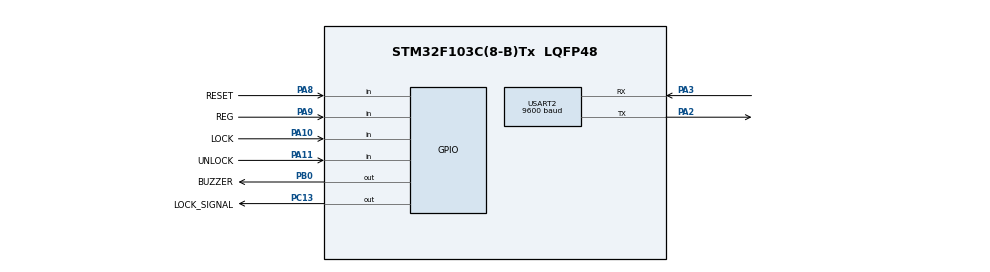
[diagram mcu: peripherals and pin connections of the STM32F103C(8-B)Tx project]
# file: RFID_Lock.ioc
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Mcu.Family=STM32F1
Mcu.Name=STM32F103C(8-B)Tx
Mcu.Package=LQFP48
NVIC.PriorityGroup=NVIC_PRIORITYGROUP_4
PA10.GPIO_Label=LOCK
PA10.GPIO_PuPd=GPIO_PULLUP
PA10.Signal=GPIO_Input
PA11.GPIO_Label=UNLOCK
PA11.GPIO_PuPd=GPIO_PULLUP
PA11.Signal=GPIO_Input
PA13.Mode=Serial_Wire
PA13.Signal=SYS_JTMS-SWDIO
PA14.Mode=Serial_Wire
PA14.Signal=SYS_JTCK-SWCLK
PA2.Mode=Asynchronous
PA2.Signal=USART2_TX
PA3.Mode=Asynchronous
PA3.Signal=USART2_RX
PA8.GPIO_Label=RESET
PA8.GPIO_PuPd=GPIO_PULLUP
PA8.Signal=GPIO_Input
PA9.GPIO_Label=REG
PA9.GPIO_PuPd=GPIO_PULLUP
PA9.Signal=GPIO_Input
PB0.GPIO_Label=BUZZER
PB0.GPIO_PuPd=GPIO_PULLUP
PB0.Signal=GPIO_Output
PC13-TAMPER-RTC.GPIO_Label=LOCK_SIGNAL
PC13-TAMPER-RTC.Signal=GPIO_Output
PD0-OSC_IN.Mode=HSE-External-Oscillator
PD0-OSC_IN.Signal=RCC_OSC_IN
PD1-OSC_OUT.Mode=HSE-External-Oscillator
PD1-OSC_OUT.Signal=RCC_OSC_OUT
ProjectManager.HeapSize=0x200
ProjectManager.StackSize=0x400
ProjectManager.TargetToolchain=STM32CubeIDE
RCC.APB1Freq_Value=8000000
RCC.APB2Freq_Value=8000000
USART2.BaudRate=9600
USART2.VirtualMode=VM_ASYNC
board=custom

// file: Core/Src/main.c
/* USER CODE BEGIN Header */
/**
  ******************************************************************************
  * @file           : main.c
  * @brief          : Main program body
  ******************************************************************************
  * @attention
  *
  * <h2><center>&copy; Copyright (c) 2022 STMicroelectronics.
  * All rights reserved.</center></h2>
  *
  * This software component is licensed by ST under BSD 3-Clause license,
  * the "License"; You may not use this file except in compliance with the
  * License. You may obtain a copy of the License at:
  *                        opensource.org/licenses/BSD-3-Clause
  *
  ******************************************************************************
  */
/* USER CODE END Header */
#include "main.h"

/* USER CODE BEGIN Includes */
#include "button.h"
#include "rc522.h"
#include "software_timer.h"
/* USER CODE END Includes */

UART_HandleTypeDef huart2;

/* USER CODE BEGIN PV */
MFRC522_Name RFID;
/* USER CODE END PV */

void SystemClock_Config(void);
static void MX_GPIO_Init(void);
static void MX_USART2_UART_Init(void);

int main(void)
{
	HAL_GPIO_WritePin(BUZZER_GPIO_Port, BUZZER_Pin, 1);

  /* MCU Configuration--------------------------------------------------------*/

  /* Reset of all peripherals, Initializes the Flash interface and the Systick. */
  HAL_Init();

  /* Configure the system clock */
  SystemClock_Config();

  /* Initialize all configured peripherals */
  MX_GPIO_Init();
  MX_USART2_UART_Init();
  /* USER CODE BEGIN 2 */
  MFRC522_Init(&RFID, &huart2);
  /* USER CODE END 2 */

  /* Infinite loop */
  while (1)
  {

  }
}

void SystemClock_Config(void)
{
  RCC_OscInitTypeDef RCC_OscInitStruct = {0};
  RCC_ClkInitTypeDef RCC_ClkInitStruct = {0};

  /** Initializes the RCC Oscillators according to the specified parameters
  * in the RCC_OscInitTypeDef structure.
  */
  RCC_OscInitStruct.OscillatorType = RCC_OSCILLATORTYPE_HSI;
  RCC_OscInitStruct.HSIState = RCC_HSI_ON;
  RCC_OscInitStruct.HSICalibrationValue = RCC_HSICALIBRATION_DEFAULT;
  RCC_OscInitStruct.PLL.PLLState = RCC_PLL_NONE;
  if (HAL_RCC_OscConfig(&RCC_OscInitStruct) != HAL_OK)
  {
    Error_Handler();
  }
  /** Initializes the CPU, AHB and APB buses clocks
  */
  RCC_ClkInitStruct.ClockType = RCC_CLOCKTYPE_HCLK|RCC_CLOCKTYPE_SYSCLK
                              |RCC_CLOCKTYPE_PCLK1|RCC_CLOCKTYPE_PCLK2;
  RCC_ClkInitStruct.SYSCLKSource = RCC_SYSCLKSOURCE_HSI;
  RCC_ClkInitStruct.AHBCLKDivider = RCC_SYSCLK_DIV1;
  RCC_ClkInitStruct.APB1CLKDivider = RCC_HCLK_DIV1;
  RCC_ClkInitStruct.APB2CLKDivider = RCC_HCLK_DIV1;

  if (HAL_RCC_ClockConfig(&RCC_ClkInitStruct, FLASH_LATENCY_0) != HAL_OK)
  {
    Error_Handler();
  }
}

static void MX_USART2_UART_Init(void)
{

  huart2.Instance = USART2;
  huart2.Init.BaudRate = 9600;
  huart2.Init.WordLength = UART_WORDLENGTH_8B;
  huart2.Init.StopBits = UART_STOPBITS_1;
  huart2.Init.Parity = UART_PARITY_NONE;
  huart2.Init.Mode = UART_MODE_TX_RX;
  huart2.Init.HwFlowCtl = UART_HWCONTROL_NONE;
  huart2.Init.OverSampling = UART_OVERSAMPLING_16;
  if (HAL_UART_Init(&huart2) != HAL_OK)
  {
    Error_Handler();
  }

}

static void MX_GPIO_Init(void)
{
  GPIO_InitTypeDef GPIO_InitStruct = {0};

  /* GPIO Ports Clock Enable */
  __HAL_RCC_GPIOC_CLK_ENABLE();
  __HAL_RCC_GPIOD_CLK_ENABLE();
  __HAL_RCC_GPIOA_CLK_ENABLE();
  __HAL_RCC_GPIOB_CLK_ENABLE();

  /*Configure GPIO pin Output Level */
  HAL_GPIO_WritePin(LOCK_SIGNAL_GPIO_Port, LOCK_SIGNAL_Pin, GPIO_PIN_RESET);

  /*Configure GPIO pin Output Level */
  HAL_GPIO_WritePin(BUZZER_GPIO_Port, BUZZER_Pin, GPIO_PIN_SET);

  /*Configure GPIO pin : LOCK_SIGNAL_Pin */
  GPIO_InitStruct.Pin = LOCK_SIGNAL_Pin;
  GPIO_InitStruct.Mode = GPIO_MODE_OUTPUT_PP;
  GPIO_InitStruct.Pull = GPIO_NOPULL;
  GPIO_InitStruct.Speed = GPIO_SPEED_FREQ_LOW;
  HAL_GPIO_Init(LOCK_SIGNAL_GPIO_Port, &GPIO_InitStruct);

  /*Configure GPIO pin : BUZZER_Pin */
  GPIO_InitStruct.Pin = BUZZER_Pin;
  GPIO_InitStruct.Mode = GPIO_MODE_OUTPUT_PP;
  GPIO_InitStruct.Pull = GPIO_PULLUP;
  GPIO_InitStruct.Speed = GPIO_SPEED_FREQ_LOW;
  HAL_GPIO_Init(BUZZER_GPIO_Port, &GPIO_InitStruct);

  /*Configure GPIO pins : RESET_Pin REG_Pin LOCK_Pin UNLOCK_Pin */
  GPIO_InitStruct.Pin = RESET_Pin|REG_Pin|LOCK_Pin|UNLOCK_Pin;
  GPIO_InitStruct.Mode = GPIO_MODE_INPUT;
  GPIO_InitStruct.Pull = GPIO_PULLUP;
  HAL_GPIO_Init(GPIOA, &GPIO_InitStruct);

}

void Error_Handler(void)
{
  __disable_irq();
  while (1)
  {
  }
}

/************************ (C) COPYRIGHT STMicroelectronics *****END OF FILE****/
